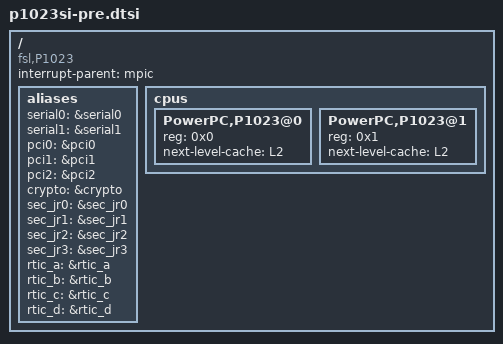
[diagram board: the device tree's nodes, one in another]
/dts-v1/;
/include/ "e500v2_power_isa.dtsi"
/ {
	compatible = "fsl,P1023";
	#address-cells = <2>;
	#size-cells = <2>;
	interrupt-parent = <&mpic>;
	aliases {
		serial0 = &serial0;
		serial1 = &serial1;
		pci0 = &pci0;
		pci1 = &pci1;
		pci2 = &pci2;
		crypto = &crypto;
		sec_jr0 = &sec_jr0;
		sec_jr1 = &sec_jr1;
		sec_jr2 = &sec_jr2;
		sec_jr3 = &sec_jr3;
		rtic_a = &rtic_a;
		rtic_b = &rtic_b;
		rtic_c = &rtic_c;
		rtic_d = &rtic_d;
	};
	cpus {
		#address-cells = <1>;
		#size-cells = <0>;
		PowerPC,P1023@0 {
			device_type = "cpu";
			reg = <0x0>;
			next-level-cache = <&L2>;
		};
		PowerPC,P1023@1 {
			device_type = "cpu";
			reg = <0x1>;
			next-level-cache = <&L2>;
		};
	};
};
